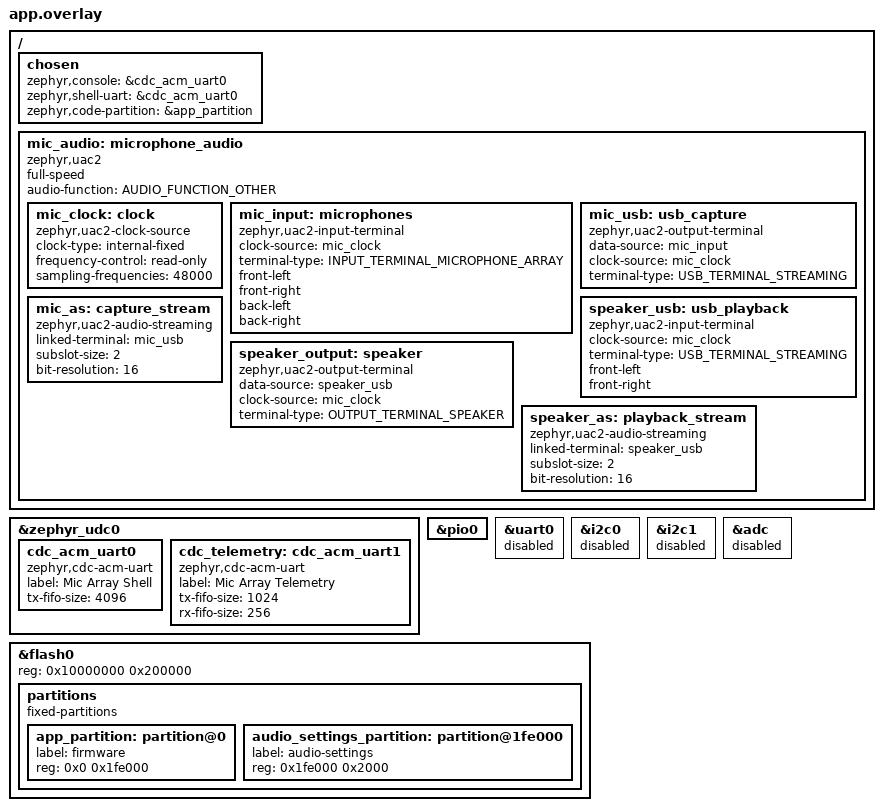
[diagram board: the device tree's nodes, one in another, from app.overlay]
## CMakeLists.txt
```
cmake_minimum_required(VERSION 3.20.0)
find_package(Zephyr REQUIRED HINTS $ENV{ZEPHYR_BASE})
project(pico2_mic_array)
target_include_directories(app PRIVATE src)
target_sources(app PRIVATE src/doa.c src/doa_control.c src/telemetry.c)
target_sources(app PRIVATE src/main.c src/dsp_parallel.c src/beamform.c src/noise_reduce.c src/nr_control.c src/usb_audio.c src/stream.c src/capture.c src/pdm_filter.c)

target_link_libraries(app PRIVATE m)

target_sources(app PRIVATE src/audio_settings.c)

target_sources(app PRIVATE src/speaker_playback.c)
```

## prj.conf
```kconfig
CONFIG_GPIO=y
CONFIG_PIO_RPI_PICO=y
# The application owns the DMA controller: the generic driver cannot chain blocks.
CONFIG_DMA=n
CONFIG_USB_DEVICE_STACK_NEXT=y
CONFIG_UART_LINE_CTRL=y
CONFIG_SHELL=y
CONFIG_SHELL_BACKEND_SERIAL=y
CONFIG_SHELL_VT100_COLORS=n
CONFIG_SHELL_STACK_SIZE=4096
CONFIG_SHELL_BACKEND_SERIAL_TX_RING_BUFFER_SIZE=4096
# Emit machine telemetry in large batches rather than 30-byte printf fragments.
CONFIG_SHELL_PRINTF_BUFF_SIZE=512
CONFIG_MAIN_STACK_SIZE=4096
CONFIG_SPEED_OPTIMIZATIONS=y
CONFIG_BUILD_OUTPUT_UF2=y
# Keep capture/USB fault counters, but omit debug-only kernel assertions and
# spinlock ownership checks from the real-time audio build.
CONFIG_ASSERT=n
CONFIG_SPIN_VALIDATE=n

CONFIG_CRC=y

# Batch full-speed USB packets to reduce per-transfer workqueue overhead.
CONFIG_USBD_CDC_ACM_BUF_POOL=y
CONFIG_USBD_CDC_ACM_BUF_POOL_SIZE=1024
CONFIG_CDC_ACM_SERIAL_INITIALIZE_AT_BOOT=n
CONFIG_USBD_AUDIO2_CLASS=y

CONFIG_FPU=y
CONFIG_FPU_SHARING=y

CONFIG_FLASH=y
CONFIG_USE_DT_CODE_PARTITION=y
CONFIG_REBOOT=y

# Windows UAC2 uses 4-byte Q16.16 explicit feedback at full speed.
CONFIG_USBD_UAC2_FS_WINDOWS_WORKAROUND=y
```

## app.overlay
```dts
#include <zephyr/dt-bindings/usb/audio.h>
/ {
	chosen {
		zephyr,console = &cdc_acm_uart0;
		zephyr,shell-uart = &cdc_acm_uart0;
	};
};

&zephyr_udc0 {
	cdc_acm_uart0: cdc_acm_uart0 {
		compatible = "zephyr,cdc-acm-uart";
		label = "Mic Array Shell";
		tx-fifo-size = <4096>;
	};
	cdc_telemetry: cdc_acm_uart1 {
		compatible = "zephyr,cdc-acm-uart";
		label = "Mic Array Telemetry";
		tx-fifo-size = <1024>;
		rx-fifo-size = <256>;
	};
};

mic_pio: &pio0 { status = "okay"; };
/* RP2354A: GP6=SCLK, GP7-GP10=DATA1-4, GP11-GP13=DIN/BCLK/LRC (U7). */
&uart0 { status = "disabled"; };
&i2c0 { status = "disabled"; };
&i2c1 { status = "disabled"; };
&adc { status = "disabled"; };

/ {
 mic_audio: microphone_audio {
  compatible = "zephyr,uac2";
  full-speed;
  audio-function = <AUDIO_FUNCTION_OTHER>;
  mic_clock: clock {
   compatible = "zephyr,uac2-clock-source";
   clock-type = "internal-fixed";
   frequency-control = "read-only";
   sampling-frequencies = <48000>;
  };
  mic_input: microphones {
   compatible = "zephyr,uac2-input-terminal";
   clock-source = <&mic_clock>;
   terminal-type = <INPUT_TERMINAL_MICROPHONE_ARRAY>;
   /* USB quad channel slots; not physical array coordinates. */
   front-left;
   front-right;
   back-left;
   back-right;
  };
  mic_usb: usb_capture {
   compatible = "zephyr,uac2-output-terminal";
   data-source = <&mic_input>;
   clock-source = <&mic_clock>;
   terminal-type = <USB_TERMINAL_STREAMING>;
  };
  mic_as: capture_stream {
   compatible = "zephyr,uac2-audio-streaming";
   linked-terminal = <&mic_usb>;
   subslot-size = <2>;
   bit-resolution = <16>;
  };
  speaker_usb: usb_playback {
   compatible = "zephyr,uac2-input-terminal";
   clock-source = <&mic_clock>;
   terminal-type = <USB_TERMINAL_STREAMING>;
   front-left; front-right;
  };
  speaker_output: speaker {
   compatible = "zephyr,uac2-output-terminal";
   data-source = <&speaker_usb>;
   clock-source = <&mic_clock>;
   terminal-type = <OUTPUT_TERMINAL_SPEAKER>;
  };
  speaker_as: playback_stream {
   compatible = "zephyr,uac2-audio-streaming";
   linked-terminal = <&speaker_usb>;
   subslot-size = <2>;
   bit-resolution = <16>;
  };
 };
};

/ { chosen { zephyr,code-partition = &app_partition; }; };
/* RP2354A has 2 MiB in-package flash; reserve the final 8 KiB for settings. */
&flash0 {
 reg = <0x10000000 0x200000>;
 ranges = <0x0 0x10000000 0x200000>;
 partitions {
  compatible = "fixed-partitions";
  #address-cells = <1>; #size-cells = <1>;
  app_partition: partition@0 { label = "firmware"; reg = <0x0 0x1fe000>; };
  audio_settings_partition: partition@1fe000 { label = "audio-settings"; reg = <0x1fe000 0x2000>; };
 };
};
```

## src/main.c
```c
#include "capture.h"
#include "board_pins.h"
#include "pdm_filter.h"
#include "dsp_parallel.h"
#include "speaker_tone.h"
#include "stream.h"
#include "usb_audio.h"
#include "speaker_playback.h"
#include "nr_control.h"
#include "doa.h"
#include <zephyr/shell/shell.h>
#include <pico/bootrom.h>
#include <zephyr/drivers/misc/pio_rpi_pico/pio_rpi_pico.h>
#include <hardware/clocks.h>
#include <hardware/timer.h>
#include <hardware/dma.h>
#include <hardware/pio_instructions.h>
#include <stdlib.h>
#include <string.h>

#define MAX_RECORD_FRAMES 16000
static struct pdm_filter filter;
static int16_t pcm[CAPTURE_FRAMES * MIC_CHANNELS];

#define RAW_BLOCKS 4
static union {
 int16_t recording[MAX_RECORD_FRAMES * MIC_CHANNELS];
 struct { uint32_t words[RAW_BLOCKS * CAPTURE_WORDS];
          int16_t pcm[RAW_BLOCKS * CAPTURE_FRAMES * MIC_CHANNELS]; } raw;
} diagnostic;
#define recording diagnostic.recording
#define raw_snapshot diagnostic.raw.words
#define raw_pcm diagnostic.raw.pcm
static atomic_t raw_request;
static unsigned raw_blocks;
static struct k_spinlock state_lock;
static struct {
	uint32_t target;
	uint32_t frames;
	uint32_t peak[MIC_CHANNELS];
	uint32_t max_process_us;
	uint32_t filter_blocks; uint64_t filter_total_us;
	bool ready;
	bool invalid;
} state;

static int cmd_boot(const struct shell *sh, size_t argc, char **argv)
{
	ARG_UNUSED(argc); ARG_UNUSED(argv);
	shell_print(sh, "Rebooting into USB BOOTSEL mode...");
	/* Allow the USB shell message to drain before disconnecting. */
	k_msleep(100);
	/* No activity GPIO; enable both mass-storage and picoboot interfaces. */
	reset_usb_boot(0, 0);
}

SHELL_CMD_ARG_REGISTER(boot, NULL, "Reboot into USB BOOTSEL mode for UF2 flashing",
		       cmd_boot, 1, 0);

static uint32_t i2s_probe[2048];
#if AUDIO_SPEAKER_DIAGNOSTICS
static uint32_t speaker_samples[32000];

/* Sample the actual output GPIOs internally, without adding jumper wires.
 * Each word packs eight chronological {LRCLK,BCLK,DIN} triples, MSB first. */
static int probe_init(PIO pio, size_t *probe_sm)
{
	const struct device *dev = DEVICE_DT_GET(DT_NODELABEL(mic_pio));
	int ret = pio_rpi_pico_allocate_sm(dev, probe_sm);
	if (ret) { return ret; }
	uint16_t instructions[] = {
		pio_encode_wait_gpio(false, SPEAKER_BCLK_PIN),
		pio_encode_wait_gpio(true, SPEAKER_BCLK_PIN),
		pio_encode_in(pio_pins, 3),
	};
	struct pio_program program = {.instructions = instructions, .length = 3, .origin = -1};
	if (!pio_can_add_program(pio, &program)) {
		pio_sm_unclaim(pio, *probe_sm);
		return -ENOMEM;
	}
	unsigned offset = pio_add_program(pio, &program);
	pio_sm_config config = pio_get_default_sm_config();
	sm_config_set_wrap(&config, offset, offset + 2);
	sm_config_set_in_pins(&config, SPEAKER_DATA_PIN);
	sm_config_set_in_shift(&config, false, true, 24);
	sm_config_set_fifo_join(&config, PIO_FIFO_JOIN_RX);
	pio_sm_init(pio, *probe_sm, offset, &config);
	return 0;
}

static int cmd_speaker_test(const struct shell *sh, size_t argc, char **argv)
{
	bool verify = strcmp(argv[0], "verify") == 0;
	unsigned frequency = 500;
	unsigned peak = 512;
	bool left_justified = false;
	if (argc > 1) {
		char *end;
		frequency = strtoul(argv[1], &end, 10);
		if (*end || frequency < 200 || frequency > 2000) { return -EINVAL; }
	}
	if (argc > 2) {
		char *end;
		peak = strtoul(argv[2], &end, 10);
		if (*end || peak > 512) { return -EINVAL; }
	}
	if (argc > 3) {
		if (strcmp(argv[3], "left") == 0) { left_justified = true; }
		else if (strcmp(argv[3], "i2s") != 0) { return -EINVAL; }
	}
	static bool initialized;
	static size_t speaker_sm;
	static unsigned format_offset[2];
	static bool probe_initialized;
	static size_t probe_sm;
	const struct device *dev = DEVICE_DT_GET(DT_NODELABEL(mic_pio));
	if (!device_is_ready(dev) || !atomic_get(&capture_stats.blocks)) {
		shell_error(sh, "Audio hardware not initialized");
		return -ENODEV;
	}
	PIO pio = pio_rpi_pico_get_pio(dev);
	if (!initialized) {
		int ret = pio_rpi_pico_allocate_sm(dev, &speaker_sm);
		if (ret) { return ret; }
		/* 32-bit stereo I2S. LR changes on the previous channel's LSB,
		 * one BCLK before the next MSB. Side-set bit0=BCLK, bit1=LRCLK. */
		uint16_t instructions[] = {
			pio_encode_out(pio_pins, 1) | pio_encode_sideset(2, 0),
			pio_encode_jmp_x_dec(0) | pio_encode_sideset(2, 1),
			pio_encode_out(pio_pins, 1) | pio_encode_sideset(2, 2),
			pio_encode_set(pio_x, 30) | pio_encode_sideset(2, 3),
			pio_encode_out(pio_pins, 1) | pio_encode_sideset(2, 2),
			pio_encode_jmp_x_dec(4) | pio_encode_sideset(2, 3),
			pio_encode_out(pio_pins, 1) | pio_encode_sideset(2, 0),
			pio_encode_set(pio_x, 30) | pio_encode_sideset(2, 1),
		};
		struct pio_program program = {
			.instructions = instructions, .length = ARRAY_SIZE(instructions), .origin = -1,
		};
		if (!pio_can_add_program(pio, &program)) {
			pio_sm_unclaim(pio, speaker_sm);
			return -ENOMEM;
		}
		unsigned offset = pio_add_program(pio, &program);
		format_offset[0] = offset;
		/* Diagnostic alternate format: align LRCLK with the MSB, as used
		 * by MAX98357B. Keep separate programs so switching is explicit. */
		uint16_t left_instructions[] = {
			pio_encode_out(pio_pins, 1) | pio_encode_sideset(2, 0),
			pio_encode_set(pio_x, 30) | pio_encode_sideset(2, 1),
			pio_encode_out(pio_pins, 1) | pio_encode_sideset(2, 0),
			pio_encode_jmp_x_dec(2) | pio_encode_sideset(2, 1),
			pio_encode_out(pio_pins, 1) | pio_encode_sideset(2, 2),
			pio_encode_set(pio_x, 30) | pio_encode_sideset(2, 3),
			pio_encode_out(pio_pins, 1) | pio_encode_sideset(2, 2),
			pio_encode_jmp_x_dec(6) | pio_encode_sideset(2, 3),
		};
		struct pio_program left_program = {
			.instructions = left_instructions, .length = 8, .origin = -1,
		};
		if (!pio_can_add_program(pio, &left_program)) {
			pio_remove_program(pio, &program, offset);
			pio_sm_unclaim(pio, speaker_sm);
			return -ENOMEM;
		}
		format_offset[1] = pio_add_program(pio, &left_program);
		pio_sm_config config = pio_get_default_sm_config();
		sm_config_set_wrap(&config, offset, offset + 7);
		sm_config_set_out_pins(&config, SPEAKER_DATA_PIN, 1);
		sm_config_set_sideset(&config, 2, false, false);
		sm_config_set_sideset_pins(&config, SPEAKER_BCLK_PIN);
		sm_config_set_out_shift(&config, false, true, 32);
		sm_config_set_fifo_join(&config, PIO_FIFO_JOIN_TX);
		sm_config_set_clkdiv(&config, (float)clock_get_hz(clk_sys) / (16000u * 128u));
		for (unsigned pin = SPEAKER_DATA_PIN; pin <= SPEAKER_LRC_PIN; pin++) { pio_gpio_init(pio, pin); }
		pio_sm_init(pio, speaker_sm, offset, &config);
		pio_sm_set_consecutive_pindirs(pio, speaker_sm, SPEAKER_DATA_PIN, 3, true);
		initialized = true;
	}
	int channel = dma_claim_unused_channel(false);
	if (channel < 0) { return -EBUSY; }
	int probe_channel = -1;
	if (verify) {
		if (!probe_initialized) {
			int ret = probe_init(pio, &probe_sm);
			if (ret) { dma_channel_unclaim(channel); return ret; }
			probe_initialized = true;
		}
		probe_channel = dma_claim_unused_channel(false);
		if (probe_channel < 0) { dma_channel_unclaim(channel); return -EBUSY; }
		pio_sm_clear_fifos(pio, probe_sm);
		pio_sm_restart(pio, probe_sm);
		unsigned bottom = (pio->sm[probe_sm].execctrl & PIO_SM0_EXECCTRL_WRAP_BOTTOM_BITS) >>
				  PIO_SM0_EXECCTRL_WRAP_BOTTOM_LSB;
		pio_sm_exec(pio, probe_sm, pio_encode_jmp(bottom));
		dma_channel_config probe_config = dma_channel_get_default_config(probe_channel);
		channel_config_set_transfer_data_size(&probe_config, DMA_SIZE_32);
		channel_config_set_read_increment(&probe_config, false);
		channel_config_set_write_increment(&probe_config, true);
		channel_config_set_dreq(&probe_config, pio_get_dreq(pio, probe_sm, false));
		dma_channel_configure(probe_channel, &probe_config, i2s_probe,
				      &pio->rxf[probe_sm], ARRAY_SIZE(i2s_probe), true);
		pio_sm_set_enabled(pio, probe_sm, true);
	}
	/* Identical L/R preserves the module's mono mix. Fade both ends and
	 * finish with 8 ms of silence; default peak 512 is about -36 dBFS. */
	uint32_t phase = 0;
	uint32_t phase_step = ((uint64_t)frequency << 32) / 16000u;
	for (unsigned n = 0; n < 16000; n++, phase += phase_step) {
		uint16_t sample = (uint16_t)speaker_tone_sample(phase, n, peak);
		speaker_samples[2 * n] = (uint32_t)sample << 16;
		speaker_samples[2 * n + 1] = (uint32_t)sample << 16;
	}
	pio_sm_set_enabled(pio, speaker_sm, false);
	pio_sm_clear_fifos(pio, speaker_sm);
	pio_sm_restart(pio, speaker_sm);
	unsigned wrap = format_offset[left_justified];
	pio_sm_set_wrap(pio, speaker_sm, wrap, wrap + 7);
	pio_sm_exec(pio, speaker_sm, pio_encode_jmp(wrap));
	pio_sm_exec(pio, speaker_sm, pio_encode_set(pio_x, 30));
	pio_sm_set_pins_with_mask(pio, speaker_sm, 0, BIT(SPEAKER_DATA_PIN) | BIT(SPEAKER_BCLK_PIN) | BIT(SPEAKER_LRC_PIN));
	dma_channel_config dma_config = dma_channel_get_default_config(channel);
	channel_config_set_transfer_data_size(&dma_config, DMA_SIZE_32);
	channel_config_set_read_increment(&dma_config, true);
	channel_config_set_write_increment(&dma_config, false);
	channel_config_set_dreq(&dma_config, pio_get_dreq(pio, speaker_sm, true));
	shell_print(sh, "Playing %u Hz for 1 second; PCM16 peak=%u; format=%s...",
		    frequency, peak, left_justified ? "left" : "i2s");
	dma_channel_configure(channel, &dma_config, &pio->txf[speaker_sm],
			      speaker_samples, ARRAY_SIZE(speaker_samples), true);
	pio_sm_set_enabled(pio, speaker_sm, true);
	int64_t deadline = k_uptime_get() + 1500;
	while (dma_channel_is_busy(channel) && k_uptime_get() < deadline) { k_msleep(5); }
	bool timed_out = dma_channel_is_busy(channel);
	k_msleep(2); /* Drain the FIFO and final shift register. */
	pio_sm_set_enabled(pio, speaker_sm, false);
	dma_channel_cleanup(channel);
	dma_channel_unclaim(channel);
	pio_sm_set_pins_with_mask(pio, speaker_sm, 0, BIT(SPEAKER_DATA_PIN) | BIT(SPEAKER_BCLK_PIN) | BIT(SPEAKER_LRC_PIN));
	if (verify) {
		bool complete = !dma_channel_is_busy(probe_channel);
		pio_sm_set_enabled(pio, probe_sm, false);
		dma_channel_cleanup(probe_channel);
		dma_channel_unclaim(probe_channel);
		if (!complete) { shell_error(sh, "I2S probe did not complete"); return -EIO; }
		shell_print(sh, "I2S_BEGIN %u", (unsigned)ARRAY_SIZE(i2s_probe));
		for (unsigned i = 0; i < ARRAY_SIZE(i2s_probe); i += 8) {
			shell_print(sh, "%08x%08x%08x%08x%08x%08x%08x%08x",
				i2s_probe[i], i2s_probe[i+1], i2s_probe[i+2], i2s_probe[i+3],
				i2s_probe[i+4], i2s_probe[i+5], i2s_probe[i+6], i2s_probe[i+7]);
		}
		shell_print(sh, "I2S_END");
	}
	if (timed_out) {
		shell_error(sh, "Speaker DMA timed out");
		return -ETIMEDOUT;
	}
	shell_print(sh, "Speaker test complete");
	return 0;
}

SHELL_STATIC_SUBCMD_SET_CREATE(speaker_commands,
	SHELL_CMD_ARG(test, NULL, "Play tone [Hz=500] [peak=512; 0..512] [i2s|left]", cmd_speaker_test, 1, 3),
	SHELL_CMD_ARG(verify, NULL, "Play tone and export GPIO samples [Hz] [peak] [i2s|left]", cmd_speaker_test, 1, 3),
	SHELL_SUBCMD_SET_END);
SHELL_CMD_REGISTER(speaker, &speaker_commands, "MAX98357A speaker", NULL);
#endif

static int cmd_stats(const struct shell *sh, size_t argc, char **argv)
{
	ARG_UNUSED(argc); ARG_UNUSED(argv);
	k_spinlock_key_t key = k_spin_lock(&state_lock);
	uint32_t peaks[MIC_CHANNELS];
	memcpy(peaks, state.peak, sizeof(peaks));
	uint32_t max_us = state.max_process_us;
	uint32_t fb = state.filter_blocks; uint64_t ft = state.filter_total_us;
	bool ready = state.ready;
	k_spin_unlock(&state_lock, key);
	shell_print(sh, "rate=%u channels=4 ready=%u blocks=%ld dropped=%ld faults=%ld max_process_us=%u",
		capture_stats.sample_rate, ready, (long)atomic_get(&capture_stats.blocks),
		(long)atomic_get(&capture_stats.dropped), (long)atomic_get(&capture_stats.faults), max_us);
	shell_print(sh, "PDM_PROFILE blocks=%u mean_us=%u", fb, fb ? (unsigned)(ft/fb) : 0);
	uint32_t local_us,remote_us,worker_status;dsp_parallel_profile(&local_us,&remote_us,&worker_status);
	shell_print(sh,"DSP_PIPELINE cores=2 fir_core0_us=%u cic_core1_us=%u worker_status=%u",local_us,remote_us,worker_status);
	shell_print(sh, "peak_pcm16=%u,%u,%u,%u", peaks[0], peaks[1], peaks[2], peaks[3]);
	return 0;
}

static int cmd_record(const struct shell *sh, size_t argc, char **argv)
{
	ARG_UNUSED(argc);
	char *end;
	unsigned long ms = strtoul(argv[1], &end, 10);
	if (*end || ms < 1 || ms > MAX_RECORD_FRAMES * 1000u / PCM_SAMPLE_RATE) {
		shell_error(sh, "Duration must be 1..%u ms (RAM diagnostic limit)", MAX_RECORD_FRAMES * 1000u / PCM_SAMPLE_RATE);
		return -EINVAL;
	}
	k_spinlock_key_t key = k_spin_lock(&state_lock);
	if (!state.ready || atomic_get(&capture_stats.faults) ||
	    (!state.invalid && state.frames < state.target)) {
		k_spin_unlock(&state_lock, key);
		shell_error(sh, "Capture warming up, faulted, or recording busy");
		return -EBUSY;
	}
	state.frames = 0;
	state.target = MIN((uint64_t)ms * capture_stats.sample_rate / 1000u, MAX_RECORD_FRAMES);
	state.invalid = false;
	k_spin_unlock(&state_lock, key);
	shell_print(sh, "RECORDING");
	return 0;
}

static int cmd_status(const struct shell *sh, size_t argc, char **argv)
{
	ARG_UNUSED(argc); ARG_UNUSED(argv);
	k_spinlock_key_t key = k_spin_lock(&state_lock);
	uint32_t frames = state.frames, target = state.target;
	bool invalid = state.invalid;
	k_spin_unlock(&state_lock, key);
	shell_print(sh, "RECORD %s %u %u", invalid ? "INVALID" :
		(target == 0 ? "EMPTY" : (frames == target ? "DONE" : "BUSY")), frames, target);
	return 0;
}

static int cmd_dump(const struct shell *sh, size_t argc, char **argv)
{
	ARG_UNUSED(argc); ARG_UNUSED(argv);
	k_spinlock_key_t key = k_spin_lock(&state_lock);
	uint32_t frames = state.frames;
	bool valid = state.target && frames == state.target && !state.invalid;
	k_spin_unlock(&state_lock, key);
	if (!valid) {
		shell_error(sh, "No complete valid recording; use mic record <ms> then mic status");
		return -EAGAIN;
	}
	/* Shell commands are serialized. A new record command cannot overwrite
	 * this completed buffer while dump is running. Capture keeps running. */
	static const char hex[] = "0123456789abcdef";
	char line[257];
	const uint8_t *bytes = (const uint8_t *)recording;
	size_t length = frames * MIC_CHANNELS * sizeof(int16_t);
	shell_print(sh, "PCM_BEGIN %u 4 %u", capture_stats.sample_rate, frames);
	for (size_t n = 0; n < length; n += 128) {
		size_t chunk = MIN(length - n, 128);
		for (size_t j = 0; j < chunk; j++) {
			line[2 * j] = hex[bytes[n + j] >> 4];
			line[2 * j + 1] = hex[bytes[n + j] & 15];
		}
		line[2 * chunk] = 0;
		shell_print(sh, "%s", line);
	}
	shell_print(sh, "PCM_END");
	return 0;
}

static int cmd_stream(const struct shell *sh, size_t argc, char **argv)
{
	ARG_UNUSED(argc);
	char *end;
	unsigned long seconds = strtoul(argv[1], &end, 10);
	if (*end || seconds < 1 || seconds > 3600) { return -EINVAL; }
	k_spinlock_key_t key = k_spin_lock(&state_lock);
	bool ready = state.ready;
	k_spin_unlock(&state_lock, key);
	if (!ready || atomic_get(&capture_stats.faults)) { return -EAGAIN; }
	return stream_run(sh, seconds);
}

static int cmd_raw(const struct shell *sh, size_t argc, char **argv)
{
	ARG_UNUSED(argc); ARG_UNUSED(argv);
	k_spinlock_key_t state_key = k_spin_lock(&state_lock);
	if (state.frames < state.target && !state.invalid) {
		k_spin_unlock(&state_lock, state_key); return -EBUSY;
	}
	state.target = 0; state.frames = 0;
	k_spin_unlock(&state_lock, state_key);
	if (atomic_get(&capture_stats.faults) || !atomic_get(&capture_stats.blocks)) {
		return -EIO;
	}
	uint32_t edges, elapsed_us;
	int ret = capture_clock_measure(&edges, &elapsed_us);
	if (ret) { return ret; }
	shell_print(sh, "PDM_CLOCK edges=%u elapsed_us=%u", edges, elapsed_us);
	raw_blocks = 0;
	atomic_set(&raw_request, 1);
	int64_t deadline = k_uptime_get() + 500;
	while (atomic_get(&raw_request) == 1 && k_uptime_get() < deadline) { k_msleep(5); }
	if (atomic_get(&raw_request) != 0) {
		atomic_set(&raw_request, 0);
		shell_error(sh, "Raw capture incomplete or discontinuous");
		return -EIO;
	}
	shell_print(sh, "RAW_BEGIN %u %u %u", PDM_CLOCK_HZ, PDM_DECIMATION,
		    (unsigned)ARRAY_SIZE(raw_snapshot));
	for (unsigned i = 0; i < ARRAY_SIZE(raw_snapshot); i += 8) {
		shell_print(sh, "%08x%08x%08x%08x%08x%08x%08x%08x",
			raw_snapshot[i], raw_snapshot[i+1], raw_snapshot[i+2], raw_snapshot[i+3],
			raw_snapshot[i+4], raw_snapshot[i+5], raw_snapshot[i+6], raw_snapshot[i+7]);
	}
	shell_print(sh, "RAW_END");
	shell_print(sh, "RAW_PCM_BEGIN %u", (unsigned)ARRAY_SIZE(raw_pcm));
	for (unsigned i = 0; i < ARRAY_SIZE(raw_pcm); i += 8) {
		shell_print(sh, "%04x%04x%04x%04x%04x%04x%04x%04x",
			(uint16_t)raw_pcm[i], (uint16_t)raw_pcm[i+1], (uint16_t)raw_pcm[i+2], (uint16_t)raw_pcm[i+3],
			(uint16_t)raw_pcm[i+4], (uint16_t)raw_pcm[i+5], (uint16_t)raw_pcm[i+6], (uint16_t)raw_pcm[i+7]);
	}
	shell_print(sh, "RAW_PCM_END");
	ret = capture_phase_read(i2s_probe, ARRAY_SIZE(i2s_probe));
	if (ret) { return ret; }
	shell_print(sh, "PHASE_BEGIN %u", (unsigned)ARRAY_SIZE(i2s_probe));
	for (unsigned i = 0; i < ARRAY_SIZE(i2s_probe); i += 8) {
		shell_print(sh, "%08x%08x%08x%08x%08x%08x%08x%08x",
			i2s_probe[i], i2s_probe[i+1], i2s_probe[i+2], i2s_probe[i+3],
			i2s_probe[i+4], i2s_probe[i+5], i2s_probe[i+6], i2s_probe[i+7]);
	}
	shell_print(sh, "PHASE_END");
	ret = capture_clock_trace(i2s_probe, ARRAY_SIZE(i2s_probe));
	if (ret) { return ret; }
	shell_print(sh, "CLOCK_TRACE_BEGIN %u %u", (unsigned)ARRAY_SIZE(i2s_probe), clock_get_hz(clk_sys));
	for (unsigned i = 0; i < ARRAY_SIZE(i2s_probe); i += 8) {
		shell_print(sh, "%08x%08x%08x%08x%08x%08x%08x%08x",
			i2s_probe[i], i2s_probe[i+1], i2s_probe[i+2], i2s_probe[i+3],
			i2s_probe[i+4], i2s_probe[i+5], i2s_probe[i+6], i2s_probe[i+7]);
	}
	shell_print(sh, "CLOCK_TRACE_END");
	return 0;
}

SHELL_STATIC_SUBCMD_SET_CREATE(mic_commands,
	SHELL_CMD_ARG(stream, NULL, "Stream binary PCM for 1..3600 seconds (host tool)", cmd_stream, 2, 0),
	SHELL_CMD(stats, NULL, "Capture health and recent per-channel peaks", cmd_stats),
	SHELL_CMD_ARG(record, NULL, "Record 1..333 ms of four-channel PCM (RAM limit)", cmd_record, 2, 0),
	SHELL_CMD(status, NULL, "Recording status", cmd_status),
	SHELL_CMD(dump, NULL, "Export completed recording as framed PCM16 hex", cmd_dump),
	SHELL_CMD(raw, NULL, "Measure GPIO clock and export raw PDM plus matching PCM", cmd_raw),
	SHELL_SUBCMD_SET_END);
SHELL_CMD_REGISTER(mic, &mic_commands, "RP2354A microphone array", NULL);

__ramfunc __attribute__((optimize("O3"))) int main(void)
{
	/* Capture outranks shell work. Any continuity failure stops acquisition,
     * allowing shell recovery instead of an overloaded conversion loop. */
	k_thread_priority_set(k_current_get(), 2);
	audio_control_restore();
	pdm_filter_init(&filter);
	int ret = usb_audio_init();
	if (ret) { return ret; }
	ret = dsp_parallel_init();
	if(ret){printk("DSP core launch failed: %d\n",ret);return ret;}
	ret = capture_start();
	if (ret) {
		atomic_inc(&capture_stats.faults);
		printk("Capture initialization failed: %d; reboot required\n", ret);
		return ret;
	}
	ret=speaker_playback_init();
	if(ret){printk("Speaker initialization failed: %d\n",ret);return ret;}
	uint32_t expected = 0;
	uint32_t warmup = 48; /* >100 ms, including microphone and CIC settling. */
	while (true) {
		struct capture_block *block;
		if (capture_read(&block, K_MSEC(100)) != 0) {
			if (atomic_get(&capture_stats.faults)) {
				k_spinlock_key_t key = k_spin_lock(&state_lock);
				state.ready = false;
				if (state.frames < state.target) { state.invalid = true; }
				k_spin_unlock(&state_lock, key);
			}
			continue;
		}
		uint32_t start = k_cycle_get_32();
		if (atomic_get(&capture_stats.faults)) {
			capture_release(block);
			k_spinlock_key_t key = k_spin_lock(&state_lock);
			state.ready = false;
			if (state.frames < state.target) { state.invalid = true; }
			k_spin_unlock(&state_lock, key);
			continue;
		}
		if (block->sequence != expected) {
            /* Lost input is fatal: never conceal it with repeated warmup silence. */
            if(atomic_get(&raw_request)==1)atomic_set(&raw_request,-1);
            capture_fail();continue;
        }
        expected=block->sequence+1;
		uint32_t filter_start = k_cycle_get_32();
		/* On timeout retain this DMA block: core 1 may still be reading it. */
		struct capture_block *completed;
        if(dsp_parallel_process(&filter,block,pcm,&completed)){capture_fail();continue;}
        if(!completed)continue;
        block=completed;
		uint32_t filter_us = k_cyc_to_us_floor32(k_cycle_get_32()-filter_start);
		if (!warmup) {
			stream_push(pcm, block->sequence);
            doa_feed(pcm,block->sequence,block->end_us);
			usb_audio_push(nr_apply(pcm), block->sequence);
		}
		if (atomic_get(&raw_request) == 1) {
			memcpy(raw_snapshot + raw_blocks * CAPTURE_WORDS, block->words,
			       CAPTURE_WORDS * sizeof(uint32_t));
			memcpy(raw_pcm + raw_blocks * CAPTURE_FRAMES * MIC_CHANNELS, pcm, sizeof(pcm));
			if (++raw_blocks == RAW_BLOCKS) { atomic_set(&raw_request, 0); }
		}
		capture_release(block);
		uint32_t peaks[MIC_CHANNELS] = {0};
		for (unsigned f = 0; f < CAPTURE_FRAMES; f++) {
			for (unsigned c = 0; c < MIC_CHANNELS; c++) {
				int32_t sample = pcm[f * MIC_CHANNELS + c];
				peaks[c] = MAX(peaks[c], (uint32_t)abs(sample));
			}
		}
		k_spinlock_key_t key = k_spin_lock(&state_lock);
		if (warmup) {
			warmup--;
		} else {
			state.ready = !atomic_get(&capture_stats.faults);
			memcpy(state.peak, peaks, sizeof(peaks));
			if (state.frames < state.target && !state.invalid) {
				uint32_t count = MIN(CAPTURE_FRAMES, state.target - state.frames);
				memcpy(recording + state.frames * MIC_CHANNELS, pcm,
				       count * MIC_CHANNELS * sizeof(int16_t));
				state.frames += count;
			}
		}
		uint32_t elapsed = k_cyc_to_us_floor32(k_cycle_get_32() - start);
		state.max_process_us = MAX(state.max_process_us, elapsed);
		state.filter_blocks++; state.filter_total_us += filter_us;
		k_spin_unlock(&state_lock, key);
		k_yield();
	}
}
```

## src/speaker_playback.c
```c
#include "speaker_playback.h"
#include "board_pins.h"
#include "audio_config.h"
#include <zephyr/kernel.h>
#include <zephyr/shell/shell.h>
#include <zephyr/drivers/misc/pio_rpi_pico/pio_rpi_pico.h>
#include <hardware/dma.h>
#include <hardware/clocks.h>
#include <hardware/pio_instructions.h>
#include <string.h>
#include <stdlib.h>
#define FRAMES 128u
#define RING 2048u
#define TARGET 1024u
#define DMA_NODE DT_NODELABEL(dma)
#define PLAY_IRQ DT_IRQ_BY_IDX(DMA_NODE,3,irq)
static int16_t ring[RING][2];
static uint32_t blocks[2][FRAMES*2];
static struct k_spinlock lock;
static PIO pio;static size_t sm;
static int channels[2];static uint32_t mask;static unsigned expected;
static struct {bool enabled,primed;unsigned read,fill;int32_t filtered;
 uint32_t received,played,packets,underruns,overruns,faults,blocks,silence,min_fill,max_fill;int peak;
} state;
static __ramfunc __attribute__((optimize("O3"))) void fill_block(unsigned slot)
{
 k_spinlock_key_t key=k_spin_lock(&lock);
 if(state.enabled && !state.primed && state.fill>=TARGET)state.primed=true;
 if(state.enabled && state.primed && state.fill<FRAMES){state.underruns++;state.primed=false;}
 unsigned available=(state.primed || !state.enabled)?MIN(state.fill,FRAMES):0;
 for(unsigned n=0;n<available;n++){
  const int16_t *s=ring[(state.read+n)&(RING-1)];
  blocks[slot][2*n]=(uint32_t)(uint16_t)s[0]<<16;
  blocks[slot][2*n+1]=(uint32_t)(uint16_t)s[1]<<16;
 }
 if(available<FRAMES){memset(blocks[slot]+available*2,0,(FRAMES-available)*8);state.silence+=FRAMES-available;}
 state.read=(state.read+available)&(RING-1);state.fill-=available;state.played+=available;
 if(!state.enabled && !state.fill)state.primed=false;
 if(available)state.min_fill=MIN(state.min_fill,state.fill);
 state.blocks++;k_spin_unlock(&lock,key);
}
static void dma_isr(const void *unused)
{
 ARG_UNUSED(unused);uint32_t pending=dma_hw->ints3&mask;
 dma_hw->ints3=pending;
 if(pending!=BIT(channels[expected])){state.faults++;dma_hw->inte3&=~mask;pio_sm_set_enabled(pio,sm,false);return;}
 unsigned slot=expected;
 if(dma_hw->ch[channels[slot]].ctrl_trig&DMA_CH0_CTRL_TRIG_AHB_ERROR_BITS){state.faults++;dma_hw->inte3&=~mask;pio_sm_set_enabled(pio,sm,false);return;}
 fill_block(slot);
 dma_channel_set_read_addr(channels[slot],blocks[slot],false);
 dma_channel_set_trans_count(channels[slot],FRAMES*2,false);expected^=1;
}
int speaker_playback_init(void)
{
 const struct device *dev=DEVICE_DT_GET(DT_NODELABEL(mic_pio));
 int result=pio_rpi_pico_allocate_sm(dev,&sm);if(result)return result;
 pio=pio_rpi_pico_get_pio(dev);
 const uint16_t instructions[]={
  pio_encode_out(pio_pins,1)|pio_encode_sideset(2,0),
  pio_encode_jmp_x_dec(0)|pio_encode_sideset(2,1),
  pio_encode_out(pio_pins,1)|pio_encode_sideset(2,2),
  pio_encode_set(pio_x,30)|pio_encode_sideset(2,3),
  pio_encode_out(pio_pins,1)|pio_encode_sideset(2,2),
  pio_encode_jmp_x_dec(4)|pio_encode_sideset(2,3),
  pio_encode_out(pio_pins,1)|pio_encode_sideset(2,0),
  pio_encode_set(pio_x,30)|pio_encode_sideset(2,1)};
 struct pio_program program={.instructions=instructions,.length=ARRAY_SIZE(instructions),.origin=-1};
 if(!pio_can_add_program(pio,&program))return -ENOMEM;
 unsigned offset=pio_add_program(pio,&program);pio_sm_config config=pio_get_default_sm_config();
 sm_config_set_wrap(&config,offset,offset+7);sm_config_set_out_pins(&config,SPEAKER_DATA_PIN,1);
 sm_config_set_sideset(&config,2,false,false);sm_config_set_sideset_pins(&config,SPEAKER_BCLK_PIN);
 sm_config_set_out_shift(&config,false,true,32);sm_config_set_fifo_join(&config,PIO_FIFO_JOIN_TX);
 sm_config_set_clkdiv(&config,(float)clock_get_hz(clk_sys)/(PCM_SAMPLE_RATE*128u));
 for(unsigned pin=SPEAKER_DATA_PIN;pin<=SPEAKER_LRC_PIN;pin++)pio_gpio_init(pio,pin);
 pio_sm_init(pio,sm,offset,&config);pio_sm_set_consecutive_pindirs(pio,sm,SPEAKER_DATA_PIN,3,true);
 pio_sm_set_pins_with_mask(pio,sm,0,BIT(SPEAKER_DATA_PIN)|BIT(SPEAKER_BCLK_PIN)|BIT(SPEAKER_LRC_PIN));
 pio_sm_exec(pio,sm,pio_encode_set(pio_x,30));
 for(unsigned i=0;i<2;i++){
  channels[i]=dma_claim_unused_channel(false);if(channels[i]<0)return -EBUSY;mask|=BIT(channels[i]);
 }
 for(unsigned i=0;i<2;i++){
  dma_channel_config config=dma_channel_get_default_config(channels[i]);
  channel_config_set_transfer_data_size(&config,DMA_SIZE_32);channel_config_set_read_increment(&config,true);
  channel_config_set_write_increment(&config,false);channel_config_set_dreq(&config,pio_get_dreq(pio,sm,true));
  channel_config_set_chain_to(&config,channels[i^1]);
  dma_channel_configure(channels[i],&config,&pio->txf[sm],blocks[i],FRAMES*2,false);
 }
 IRQ_CONNECT(PLAY_IRQ,2,dma_isr,NULL,0);dma_hw->ints3=mask;dma_hw->inte3|=mask;irq_enable(PLAY_IRQ);
 dma_start_channel_mask(BIT(channels[0]));pio_sm_set_enabled(pio,sm,true);return 0;
}
void speaker_playback_enable(bool enabled)
{
 k_spinlock_key_t key=k_spin_lock(&lock);state.enabled=enabled;
 if(enabled){state.primed=false;state.read=state.fill=0;}
 state.filtered=TARGET*256;state.min_fill=RING;k_spin_unlock(&lock,key);
}
bool speaker_playback_active(void){k_spinlock_key_t key=k_spin_lock(&lock);bool value=state.enabled;k_spin_unlock(&lock,key);return value;}
__ramfunc __attribute__((optimize("O3"))) void speaker_playback_receive(const int16_t *pcm,unsigned frames)
{
 k_spinlock_key_t key=k_spin_lock(&lock);
 if(state.enabled){
  if(state.fill+frames>RING){state.overruns++;state.primed=false;state.fill=state.read=0;}
  if(frames<=RING){
   for(unsigned n=0;n<frames;n++){
    unsigned write=(state.read+state.fill+n)&(RING-1);
    ring[write][0]=pcm[2*n];ring[write][1]=pcm[2*n+1];
    state.peak=MAX(state.peak,MAX(abs((int)pcm[2*n]),abs((int)pcm[2*n+1])));
   }
   state.fill+=frames;state.received+=frames;state.packets++;state.max_fill=MAX(state.max_fill,state.fill);
  }
 }
 k_spin_unlock(&lock,key);
}
uint32_t speaker_playback_feedback(void)
{
 k_spinlock_key_t key=k_spin_lock(&lock);
 state.filtered+=((int32_t)state.fill*256-state.filtered)/64;
 int32_t correction=state.primed?CLAMP((state.filtered/256-(int32_t)TARGET)*2,-1638,1638):0;
 k_spin_unlock(&lock,key);return (48u<<14)-correction;
}
static int stats(const struct shell *sh,size_t argc,char **argv)
{
 ARG_UNUSED(argc);ARG_UNUSED(argv);k_spinlock_key_t key=k_spin_lock(&lock);__typeof__(state) s=state;k_spin_unlock(&lock,key);
 shell_print(sh,"SPEAKER enabled=%u primed=%u fill=%u packets=%u received=%u played=%u underruns=%u overruns=%u faults=%u silence=%u min_fill=%u max_fill=%u peak=%d rate=48000 channels=2",s.enabled,s.primed,s.fill,s.packets,s.received,s.played,s.underruns,s.overruns,s.faults,s.silence,s.min_fill,s.max_fill,s.peak);return 0;
}
SHELL_CMD_REGISTER(spkstats,NULL,"UAC2 playback / PIO I2S DMA health",stats);
```

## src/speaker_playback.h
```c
#ifndef SPEAKER_PLAYBACK_H
#define SPEAKER_PLAYBACK_H
#include <stdbool.h>
#include <stdint.h>
int speaker_playback_init(void);
void speaker_playback_enable(bool enabled);
bool speaker_playback_active(void);
void speaker_playback_receive(const int16_t *pcm,unsigned frames);
uint32_t speaker_playback_feedback(void);
#endif
```

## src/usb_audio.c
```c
#include "usb_audio.h"
#include "speaker_playback.h"
#include "capture.h"
#include <zephyr/usb/usbd.h>
#include <zephyr/usb/class/usbd_uac2.h>
#include <zephyr/shell/shell.h>
#include <string.h>

#define RING_FRAMES 2048
/* Keep a 32-ms producer reserve: CDC/control bursts can postpone capture
 * delivery beyond the former 16-ms reserve. No additional ring RAM is used. */
#define PRIME_FRAMES 1536
#define LOW_FRAMES 1280
#define HIGH_FRAMES 1792
#define TERMINAL UAC2_ENTITY_ID(DT_NODELABEL(mic_usb))
static const struct device *const audio = DEVICE_DT_GET(DT_NODELABEL(mic_audio));
USBD_DEVICE_DEFINE(mic_usb_device, DEVICE_DT_GET(DT_NODELABEL(zephyr_udc0)), 0x2fe3, 0x0007);
USBD_DESC_LANG_DEFINE(mic_lang);
USBD_DESC_MANUFACTURER_DEFINE(mic_mfr, "Pico Array Prototype");
USBD_DESC_PRODUCT_DEFINE(mic_product, "Pico 2 Mic Array UAC2");
USBD_DESC_SERIAL_NUMBER_DEFINE(mic_serial);
USBD_DESC_CONFIG_DEFINE(mic_config_desc, "Audio, shell and telemetry");
USBD_CONFIGURATION_DEFINE(mic_config, 0, 100, &mic_config_desc);
K_MEM_SLAB_DEFINE(audio_packets, ROUND_UP(49 * 8, UDC_BUF_GRANULARITY), 8, UDC_BUF_ALIGN);
static int16_t ring[RING_FRAMES][4];
static struct k_spinlock lock;
static struct {
	bool enabled, primed, have_sequence, pattern;
	unsigned read, fill;
	uint32_t expected, starts, stops, in_frames, out_frames;
	uint32_t packets, short_packets, long_packets, startup_silence;
	uint32_t underruns, overruns, gaps, send_errors, pool_errors;
	uint32_t epoch, busy_startup, busy_active;
	unsigned min_fill, max_fill;
} state;

bool usb_audio_active(void)
{
 k_spinlock_key_t key = k_spin_lock(&lock);
 bool active = state.enabled || speaker_playback_active(); k_spin_unlock(&lock, key); return active;
}

__ramfunc __attribute__((optimize("O3"))) void usb_audio_push(const int16_t *pcm, uint32_t sequence)
{
	k_spinlock_key_t key = k_spin_lock(&lock);
	if (!state.enabled) { k_spin_unlock(&lock, key); return; }
	if (state.have_sequence && sequence != state.expected) {
		state.gaps++; state.epoch++; state.fill = 0; state.read = 0; state.primed = false;
	}
	state.have_sequence = true; state.expected = sequence + 1;
	if (state.fill + CAPTURE_FRAMES > RING_FRAMES) {
		state.overruns++; state.epoch++; state.fill = 0; state.read = 0; state.primed = false;
	}
	for (unsigned n = 0; n < CAPTURE_FRAMES; n++) {
		int16_t *frame = ring[(state.read + state.fill + n) % RING_FRAMES];
		if (state.pattern) {
			uint16_t value = sequence * CAPTURE_FRAMES + n;
			frame[0] = value; frame[1] = value ^ 0x1357;
			frame[2] = value ^ 0x2468; frame[3] = value ^ 0x55aa;
		} else { memcpy(frame, pcm + n*4, 8); }
	}
	state.fill += CAPTURE_FRAMES; state.in_frames += CAPTURE_FRAMES;
	state.max_fill = MAX(state.max_fill, state.fill);
	k_spin_unlock(&lock, key);
}

static void terminal_update(const struct device *dev, uint8_t terminal,
			    bool enabled, bool microframes, void *user)
{
	ARG_UNUSED(dev); ARG_UNUSED(user);
	if(terminal==UAC2_ENTITY_ID(DT_NODELABEL(speaker_usb))){speaker_playback_enable(enabled && !microframes);return;}
	if (terminal != TERMINAL) { return; }
	k_spinlock_key_t key = k_spin_lock(&lock);
	state.enabled = enabled && !microframes;
	state.primed = false; state.have_sequence = false;
	state.fill = 0; state.read = 0; state.epoch++;
	if (enabled) { state.min_fill = RING_FRAMES; }
	if (enabled) { state.starts++; } else { state.stops++; }
	k_spin_unlock(&lock, key);
}

static void release_packet(const struct device *dev, uint8_t terminal, void *buf, void *user)
{
	ARG_UNUSED(dev); ARG_UNUSED(terminal); ARG_UNUSED(user);
	k_mem_slab_free(&audio_packets, buf);
}

static __ramfunc __attribute__((optimize("O3"))) void sof(const struct device *dev, void *user)
{
	ARG_UNUSED(user);
	k_spinlock_key_t key = k_spin_lock(&lock);
	bool enabled = state.enabled;
	k_spin_unlock(&lock, key);
	if (!enabled) { return; }
	int16_t *packet;
	if (k_mem_slab_alloc(&audio_packets, (void **)&packet, K_NO_WAIT)) {
		key = k_spin_lock(&lock); state.pool_errors++; k_spin_unlock(&lock, key); return;
	}
	unsigned frames = PCM_SAMPLE_RATE / 1000u;
	bool staged = false;
	key = k_spin_lock(&lock);
	uint32_t epoch = state.epoch;
	if (!state.primed && state.fill >= PRIME_FRAMES) { state.primed = true; }
	if (state.primed) {
		/* 128-frame producer blocks cause a 2.67-ms sawtooth. Wide deadband
		 * absorbs that jitter; +/- one complete frame handles clock drift. */
		if (state.fill < LOW_FRAMES) { frames = 47; }
		if (state.fill > HIGH_FRAMES) { frames = 49; }
		if (state.fill < frames) {
			state.underruns++; state.primed = false;
		} else {
			for (unsigned n = 0; n < frames; n++) {
				memcpy(packet + n*4, ring[(state.read + n) % RING_FRAMES], 8);
			}
			staged = true;
		}
	}
	if (!state.primed) {
		memset(packet, 0, frames*8); state.startup_silence += frames;
	}
	k_spin_unlock(&lock, key);
	int ret = usbd_uac2_send(dev, TERMINAL, packet, frames*8);
	key = k_spin_lock(&lock);
	if (ret == -EAGAIN) {
		if (staged) { state.busy_active++; } else { state.busy_startup++; }
	} else if (ret) { state.send_errors++; }
	else {
		if (staged && state.epoch == epoch) {
			state.read = (state.read + frames) % RING_FRAMES;
			state.fill -= frames; state.out_frames += frames;
			state.min_fill = MIN(state.min_fill, state.fill);
		}
		state.packets++;
		if (frames == 47) { state.short_packets++; }
		if (frames == 49) { state.long_packets++; }
	}
	k_spin_unlock(&lock, key);
	if (ret) { k_mem_slab_free(&audio_packets, packet); }
}

K_MEM_SLAB_DEFINE(playback_packets,ROUND_UP(49*4,UDC_BUF_GRANULARITY),4,UDC_BUF_ALIGN);
static void *receive_buffer(const struct device *dev,uint8_t terminal,uint16_t size,void *user)
{
 ARG_UNUSED(dev);ARG_UNUSED(user);void *buffer=NULL;
 if(terminal!=UAC2_ENTITY_ID(DT_NODELABEL(speaker_usb)) || size>49*4)return NULL;
 if(k_mem_slab_alloc(&playback_packets,&buffer,K_NO_WAIT))return NULL;
 return buffer;
}
static void receive_data(const struct device *dev,uint8_t terminal,void *buffer,uint16_t size,void *user)
{
 ARG_UNUSED(dev);ARG_UNUSED(user);
 if(terminal==UAC2_ENTITY_ID(DT_NODELABEL(speaker_usb)) && size && !(size%4))speaker_playback_receive(buffer,size/4);
 k_mem_slab_free(&playback_packets,buffer);
}
static uint32_t playback_feedback(const struct device *dev,uint8_t terminal,void *user)
{ARG_UNUSED(dev);ARG_UNUSED(terminal);ARG_UNUSED(user);return speaker_playback_feedback();}
static const struct uac2_ops ops = {
	.get_recv_buf=receive_buffer,.data_recv_cb=receive_data,.feedback_cb=playback_feedback,
	.sof_cb = sof, .terminal_update_cb = terminal_update, .buf_release_cb = release_packet,
};

int usb_audio_init(void)
{
	usbd_uac2_set_ops(audio, &ops, NULL);
	int ret;
#define CHECK(call) do { ret = (call); if (ret) { return ret; } } while (0)
	CHECK(usbd_add_descriptor(&mic_usb_device, &mic_lang));
	CHECK(usbd_add_descriptor(&mic_usb_device, &mic_mfr));
	CHECK(usbd_add_descriptor(&mic_usb_device, &mic_product));
	CHECK(usbd_add_descriptor(&mic_usb_device, &mic_serial));
	CHECK(usbd_add_configuration(&mic_usb_device, USBD_SPEED_FS, &mic_config));
	CHECK(usbd_register_class(&mic_usb_device, "cdc_acm_0", USBD_SPEED_FS, 1));
	CHECK(usbd_register_class(&mic_usb_device, "cdc_acm_1", USBD_SPEED_FS, 1));
	CHECK(usbd_register_class(&mic_usb_device, "uac2_0", USBD_SPEED_FS, 1));
	CHECK(usbd_device_set_code_triple(&mic_usb_device, USBD_SPEED_FS, USB_BCC_MISCELLANEOUS, 2, 1));
	CHECK(usbd_init(&mic_usb_device));
	CHECK(usbd_enable(&mic_usb_device));
	return 0;
}

static int stats(const struct shell *sh, size_t argc, char **argv)
{
	ARG_UNUSED(argc); ARG_UNUSED(argv);
	k_spinlock_key_t key = k_spin_lock(&lock);
	__typeof__(state) snapshot = state;
	k_spin_unlock(&lock, key);
	shell_print(sh, "UAC enabled=%u primed=%u fill=%u starts=%u stops=%u packets=%u in=%u out=%u short=%u long=%u silence=%u underruns=%u overruns=%u gaps=%u send_errors=%u pool_errors=%u min_fill=%u max_fill=%u busy_startup=%u busy_active=%u",
		snapshot.enabled, snapshot.primed, snapshot.fill, snapshot.starts, snapshot.stops,
		snapshot.packets, snapshot.in_frames, snapshot.out_frames, snapshot.short_packets,
		snapshot.long_packets, snapshot.startup_silence, snapshot.underruns, snapshot.overruns,
		snapshot.gaps, snapshot.send_errors, snapshot.pool_errors, snapshot.min_fill, snapshot.max_fill,
		snapshot.busy_startup, snapshot.busy_active);
	return 0;
}
SHELL_CMD_REGISTER(uacstats, NULL, "USB audio health (cumulative since reboot)", stats);

static int pattern_cmd(const struct shell *sh, size_t argc, char **argv)
{
	ARG_UNUSED(argc);
	if (strcmp(argv[1], "on") && strcmp(argv[1], "off")) { return -EINVAL; }
	k_spinlock_key_t key = k_spin_lock(&lock);
	if (state.enabled) { k_spin_unlock(&lock, key); return -EBUSY; }
	state.pattern = !strcmp(argv[1], "on");
	bool enabled = state.pattern;
	k_spin_unlock(&lock, key);
	shell_print(sh, "UAC_PATTERN %s", enabled ? "ON" : "OFF");
	return 0;
}
SHELL_CMD_ARG_REGISTER(uacpattern, NULL, "Diagnostic ramp on/off; close audio first", pattern_cmd, 2, 0);
```
